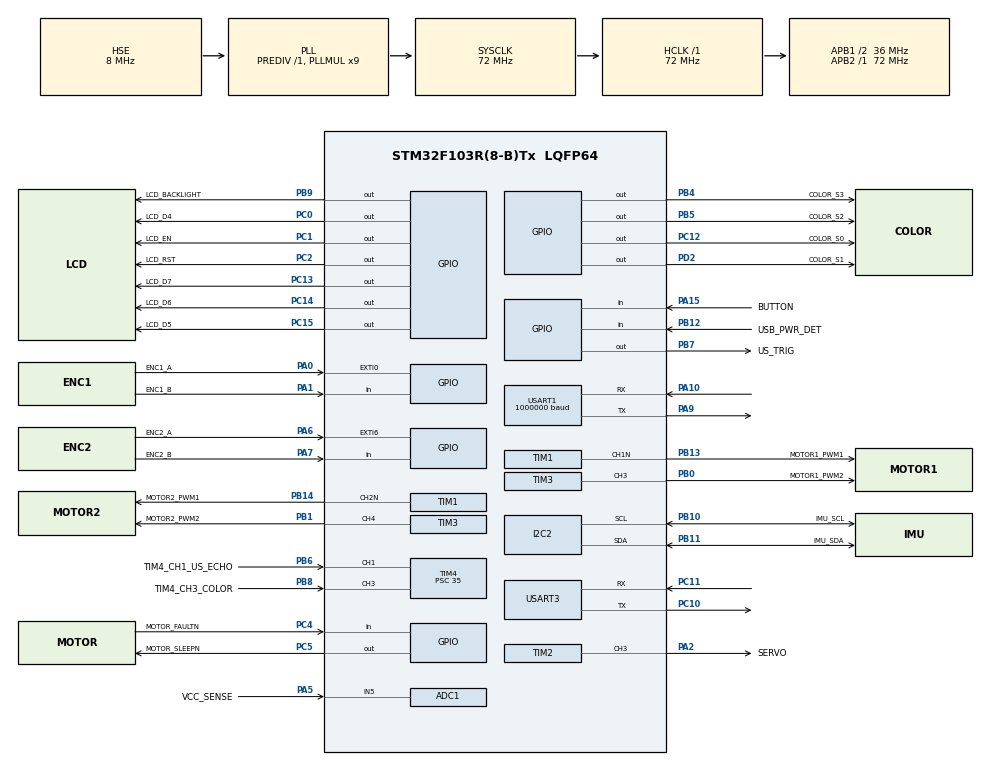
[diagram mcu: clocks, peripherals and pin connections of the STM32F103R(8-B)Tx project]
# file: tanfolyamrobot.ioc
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ADC1.Channel-0\#ChannelRegularConversion=ADC_CHANNEL_5
ADC1.ContinuousConvMode=DISABLE
ADC1.NbrOfConversion=1
ADC1.NbrOfConversionFlag=1
ADC1.Rank-0\#ChannelRegularConversion=1
ADC1.SamplingTime-0\#ChannelRegularConversion=ADC_SAMPLETIME_239CYCLES_5
ADC1.master=1
Dma.Request0=USART1_TX
Dma.Request1=USART3_TX
Dma.USART1_TX.0.Direction=DMA_MEMORY_TO_PERIPH
Dma.USART1_TX.0.Instance=DMA1_Channel4
Dma.USART1_TX.0.MemDataAlignment=DMA_MDATAALIGN_BYTE
Dma.USART1_TX.0.MemInc=DMA_MINC_ENABLE
Dma.USART1_TX.0.Mode=DMA_NORMAL
Dma.USART1_TX.0.PeriphDataAlignment=DMA_PDATAALIGN_BYTE
Dma.USART1_TX.0.PeriphInc=DMA_PINC_DISABLE
Dma.USART1_TX.0.Priority=DMA_PRIORITY_HIGH
Dma.USART3_TX.1.Direction=DMA_MEMORY_TO_PERIPH
Dma.USART3_TX.1.Instance=DMA1_Channel2
Dma.USART3_TX.1.MemDataAlignment=DMA_MDATAALIGN_BYTE
Dma.USART3_TX.1.MemInc=DMA_MINC_ENABLE
Dma.USART3_TX.1.Mode=DMA_NORMAL
Dma.USART3_TX.1.PeriphDataAlignment=DMA_PDATAALIGN_BYTE
Dma.USART3_TX.1.PeriphInc=DMA_PINC_DISABLE
Dma.USART3_TX.1.Priority=DMA_PRIORITY_HIGH
I2C2.I2C_Mode=I2C_Fast
Mcu.Family=STM32F1
Mcu.Name=STM32F103R(8-B)Tx
Mcu.Package=LQFP64
NVIC.ADC1_2_IRQn=true\:15\:0\:true\:false\:true\:true\:true\:true
NVIC.DMA1_Channel2_IRQn=true\:0\:0\:true\:false\:true\:false\:true\:true
NVIC.DMA1_Channel4_IRQn=true\:0\:0\:true\:false\:true\:false\:true\:true
NVIC.EXTI0_IRQn=true\:2\:0\:true\:false\:true\:true\:true\:true
NVIC.EXTI9_5_IRQn=true\:2\:0\:true\:false\:true\:true\:true\:true
NVIC.I2C2_EV_IRQn=true\:0\:0\:false\:false\:true\:true\:true\:true
NVIC.PriorityGroup=NVIC_PRIORITYGROUP_4
NVIC.TIM1_UP_IRQn=true\:2\:0\:true\:false\:true\:true\:true\:true
NVIC.TIM2_IRQn=true\:2\:0\:true\:false\:true\:true\:true\:true
NVIC.TIM4_IRQn=true\:2\:0\:true\:false\:true\:true\:true\:true
NVIC.USART1_IRQn=true\:0\:0\:true\:false\:true\:true\:true\:true
NVIC.USART3_IRQn=true\:0\:0\:false\:false\:true\:true\:true\:true
PA0-WKUP.GPIO_Label=ENC1_A
PA0-WKUP.GPIO_ModeDefaultEXTI=GPIO_MODE_IT_RISING
PA0-WKUP.Signal=GPXTI0
PA1.GPIO_Label=ENC1_B
PA1.Signal=GPIO_Input
PA10.Mode=Asynchronous
PA10.Signal=USART1_RX
PA13.Mode=Trace_Asynchronous_SW
PA13.Signal=SYS_JTMS-SWDIO
PA14.Mode=Trace_Asynchronous_SW
PA14.Signal=SYS_JTCK-SWCLK
PA15.GPIO_Label=BUTTON
PA15.GPIO_PuPd=GPIO_PULLUP
PA15.Signal=GPIO_Input
PA2.GPIO_Label=SERVO
PA2.Signal=S_TIM2_CH3
PA5.GPIO_Label=VCC_SENSE
PA5.Signal=ADCx_IN5
PA6.GPIO_Label=ENC2_A
PA6.GPIO_ModeDefaultEXTI=GPIO_MODE_IT_RISING
PA6.Signal=GPXTI6
PA7.GPIO_Label=ENC2_B
PA7.Signal=GPIO_Input
PA9.Mode=Asynchronous
PA9.Signal=USART1_TX
PB0.GPIO_Label=MOTOR1_PWM2
PB0.Signal=S_TIM3_CH3
PB1.GPIO_Label=MOTOR2_PWM2
PB1.Signal=S_TIM3_CH4
PB10.GPIO_Label=IMU_SCL
PB10.GPIO_Pu=GPIO_PULLUP
PB10.Mode=I2C
PB10.Signal=I2C2_SCL
PB11.GPIO_Label=IMU_SDA
PB11.GPIO_Pu=GPIO_PULLUP
PB11.Mode=I2C
PB11.Signal=I2C2_SDA
PB12.GPIO_Label=USB_PWR_DET
PB12.GPIO_PuPd=GPIO_PULLDOWN
PB12.Signal=GPIO_Input
PB13.GPIO_Label=MOTOR1_PWM1
PB13.Mode=PWM Generation1 CH1N
PB13.Signal=TIM1_CH1N
PB14.GPIO_Label=MOTOR2_PWM1
PB14.Mode=PWM Generation2 CH2N
PB14.Signal=TIM1_CH2N
PB3.Mode=Trace_Asynchronous_SW
PB3.Signal=SYS_JTDO-TRACESWO
PB4.GPIO_Label=COLOR_S3
PB4.Signal=GPIO_Output
PB5.GPIO_Label=COLOR_S2
PB5.Signal=GPIO_Output
PB6.GPIO_Label=TIM4_CH1_US_ECHO
PB6.Signal=S_TIM4_CH1
PB7.GPIO_Label=US_TRIG
PB7.GPIO_ModeDefaultOutputPP=GPIO_MODE_OUTPUT_OD
PB7.Signal=GPIO_Output
PB8.GPIO_Label=TIM4_CH3_COLOR
PB8.Signal=S_TIM4_CH3
PB9.GPIO_Label=LCD_BACKLIGHT
PB9.PinState=GPIO_PIN_RESET
PB9.Signal=GPIO_Output
PC0.GPIO_Label=LCD_D4
PC0.Signal=GPIO_Output
PC1.GPIO_Label=LCD_EN
PC1.Signal=GPIO_Output
PC10.Mode=Asynchronous
PC10.Signal=USART3_TX
PC11.Mode=Asynchronous
PC11.Signal=USART3_RX
PC12.GPIO_Label=COLOR_S0
PC12.Signal=GPIO_Output
PC13-TAMPER-RTC.GPIO_Label=LCD_D7
PC13-TAMPER-RTC.Signal=GPIO_Output
PC14-OSC32_IN.GPIO_Label=LCD_D6
PC14-OSC32_IN.Signal=GPIO_Output
PC15-OSC32_OUT.GPIO_Label=LCD_D5
PC15-OSC32_OUT.Signal=GPIO_Output
PC2.GPIO_Label=LCD_RST
PC2.Signal=GPIO_Output
PC4.GPIO_Label=MOTOR_FAULTN
PC4.GPIO_PuPd=GPIO_PULLUP
PC4.Signal=GPIO_Input
PC5.GPIO_Label=MOTOR_SLEEPN
PC5.PinState=GPIO_PIN_RESET
PC5.Signal=GPIO_Output
PD0-OSC_IN.Mode=HSE-External-Oscillator
PD0-OSC_IN.Signal=RCC_OSC_IN
PD1-OSC_OUT.Mode=HSE-External-Oscillator
PD1-OSC_OUT.Signal=RCC_OSC_OUT
PD2.GPIO_Label=COLOR_S1
PD2.Signal=GPIO_Output
ProjectManager.HeapSize=0x2000
ProjectManager.StackSize=0x800
ProjectManager.TargetToolchain=CMake
RCC.ADCPresc=RCC_ADCPCLK2_DIV6
RCC.AHBFreq_Value=72000000
RCC.APB1CLKDivider=RCC_HCLK_DIV2
RCC.APB1Freq_Value=36000000
RCC.APB1TimFreq_Value=72000000
RCC.APB2Freq_Value=72000000
RCC.APB2TimFreq_Value=72000000
RCC.HCLKFreq_Value=72000000
RCC.PLLMUL=RCC_PLL_MUL9
RCC.PLLSourceVirtual=RCC_PLLSOURCE_HSE
RCC.SYSCLKFreq_VALUE=72000000
RCC.SYSCLKSource=RCC_SYSCLKSOURCE_PLLCLK
RCC.USBFreq_Value=72000000
SH.ADCx_IN5.0=ADC1_IN5,IN5
SH.S_TIM2_CH3.0=TIM2_CH3,PWM Generation3 CH3
SH.S_TIM3_CH3.0=TIM3_CH3,PWM Generation3 CH3
SH.S_TIM3_CH4.0=TIM3_CH4,PWM Generation4 CH4
SH.S_TIM4_CH1.0=TIM4_CH1,Input_Capture1_from_TI1
SH.S_TIM4_CH3.0=TIM4_CH3,Input_Capture3_from_TI3
TIM1.AutoReloadPreload=TIM_AUTORELOAD_PRELOAD_ENABLE
TIM1.Channel-PWM\ Generation1\ CH1N=TIM_CHANNEL_1
TIM1.Channel-PWM\ Generation2\ CH2N=TIM_CHANNEL_2
TIM1.Period=4500
TIM1.Prescaler=0
TIM2.AutoReloadPreload=TIM_AUTORELOAD_PRELOAD_ENABLE
TIM2.Channel-PWM\ Generation3\ CH3=TIM_CHANNEL_3
TIM2.OCPolarity_3=TIM_OCPOLARITY_LOW
TIM2.Period=20000
TIM2.Prescaler=71
TIM3.AutoReloadPreload=TIM_AUTORELOAD_PRELOAD_ENABLE
TIM3.Channel-PWM\ Generation3\ CH3=TIM_CHANNEL_3
TIM3.Channel-PWM\ Generation4\ CH4=TIM_CHANNEL_4
TIM3.Period=4500
TIM3.Prescaler=0
TIM4.AutoReloadPreload=TIM_AUTORELOAD_PRELOAD_ENABLE
TIM4.Channel-Input_Capture1_from_TI1=TIM_CHANNEL_1
TIM4.Channel-Input_Capture2_from_TI1_63=TIM_CHANNEL_2
TIM4.Channel-Input_Capture3_from_TI3=TIM_CHANNEL_3
TIM4.Channel-Output\ Compare4\ No\ Output=TIM_CHANNEL_4
TIM4.CounterMode=TIM_COUNTERMODE_UP
TIM4.ICPolarity_CH1=TIM_INPUTCHANNELPOLARITY_RISING
TIM4.ICPolarity_CH2=TIM_INPUTCHANNELPOLARITY_FALLING
TIM4.Period=0xffff
TIM4.Prescaler=35
USART1.BaudRate=1000000
USART1.VirtualMode=VM_ASYNC
USART3.VirtualMode=VM_ASYNC
VP_TIM1_VS_ClockSourceINT.Mode=Internal
VP_TIM2_VS_ClockSourceINT.Mode=Internal
VP_TIM3_VS_ClockSourceINT.Mode=Internal
VP_TIM4_VS_ClockSourceINT.Mode=Internal
VP_TIM4_VS_indirect_ch1.Mode=Input_Capture2_from_TI1_63
VP_TIM4_VS_no_output4.Mode=Output Compare4 No Output
board=custom

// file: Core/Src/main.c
/* USER CODE BEGIN Header */
/**
 ******************************************************************************
 * @file           : main.c
 * @brief          : Main program body
 ******************************************************************************
 * @attention
 *
 * <h2><center>&copy; Copyright (c) 2020 STMicroelectronics.
 * All rights reserved.</center></h2>
 *
 * This software component is licensed by ST under BSD 3-Clause license,
 * the "License"; You may not use this file except in compliance with the
 * License. You may obtain a copy of the License at:
 *                        opensource.org/licenses/BSD-3-Clause
 *
 ******************************************************************************
 */
/* USER CODE END Header */
#include "main.h"
#include "adc.h"
#include "dma.h"
#include "gpio.h"
#include "i2c.h"
#include "tim.h"
#include "usart.h"

/* USER CODE BEGIN Includes */
#include "Main/main_interface.h"
/* USER CODE END Includes */

void SystemClock_Config(void);

int main(void) {

  /* MCU Configuration--------------------------------------------------------*/

  /* Reset of all peripherals, Initializes the Flash interface and the Systick.
   */
  HAL_Init();

  /* Configure the system clock */
  SystemClock_Config();

  /* Initialize all configured peripherals */
  MX_GPIO_Init();
  MX_DMA_Init();
  MX_TIM4_Init();
  MX_USART1_UART_Init();
  MX_USART3_UART_Init();
  MX_TIM3_Init();
  MX_TIM1_Init();
  MX_TIM2_Init();
  MX_ADC1_Init();
  MX_I2C2_Init();
  /* USER CODE BEGIN 2 */

  main_initRobot();
  main_runRobot();

  /* USER CODE END 2 */

  /* Infinite loop */
  while (1) {

  }
}

void SystemClock_Config(void) {
  RCC_OscInitTypeDef RCC_OscInitStruct = {0};
  RCC_ClkInitTypeDef RCC_ClkInitStruct = {0};
  RCC_PeriphCLKInitTypeDef PeriphClkInit = {0};

  /** Initializes the RCC Oscillators according to the specified parameters
   * in the RCC_OscInitTypeDef structure.
   */
  RCC_OscInitStruct.OscillatorType = RCC_OSCILLATORTYPE_HSE;
  RCC_OscInitStruct.HSEState = RCC_HSE_ON;
  RCC_OscInitStruct.HSEPredivValue = RCC_HSE_PREDIV_DIV1;
  RCC_OscInitStruct.HSIState = RCC_HSI_ON;
  RCC_OscInitStruct.PLL.PLLState = RCC_PLL_ON;
  RCC_OscInitStruct.PLL.PLLSource = RCC_PLLSOURCE_HSE;
  RCC_OscInitStruct.PLL.PLLMUL = RCC_PLL_MUL9;
  if (HAL_RCC_OscConfig(&RCC_OscInitStruct) != HAL_OK) {
    Error_Handler();
  }

  /** Initializes the CPU, AHB and APB buses clocks
   */
  RCC_ClkInitStruct.ClockType = RCC_CLOCKTYPE_HCLK | RCC_CLOCKTYPE_SYSCLK |
                                RCC_CLOCKTYPE_PCLK1 | RCC_CLOCKTYPE_PCLK2;
  RCC_ClkInitStruct.SYSCLKSource = RCC_SYSCLKSOURCE_PLLCLK;
  RCC_ClkInitStruct.AHBCLKDivider = RCC_SYSCLK_DIV1;
  RCC_ClkInitStruct.APB1CLKDivider = RCC_HCLK_DIV2;
  RCC_ClkInitStruct.APB2CLKDivider = RCC_HCLK_DIV1;

  if (HAL_RCC_ClockConfig(&RCC_ClkInitStruct, FLASH_LATENCY_2) != HAL_OK) {
    Error_Handler();
  }
  PeriphClkInit.PeriphClockSelection = RCC_PERIPHCLK_ADC;
  PeriphClkInit.AdcClockSelection = RCC_ADCPCLK2_DIV6;
  if (HAL_RCCEx_PeriphCLKConfig(&PeriphClkInit) != HAL_OK) {
    Error_Handler();
  }
}

void Error_Handler(void) {
}
#ifdef USE_FULL_ASSERT
/**
 * @brief  Reports the name of the source file and the source line number
 *         where the assert_param error has occurred.
 * @param  file: pointer to the source file name
 * @param  line: assert_param error line source number
 * @retval None
 */
void assert_failed(uint8_t* file, uint32_t line) {
  /* USER CODE BEGIN 6 */
  /* User can add his own implementation to report the file name and line
     number, tex: printf("Wrong parameters value: file %s on line %d\r\n", file,
     line) */
  /* USER CODE END 6 */
}
#endif /* USE_FULL_ASSERT */
